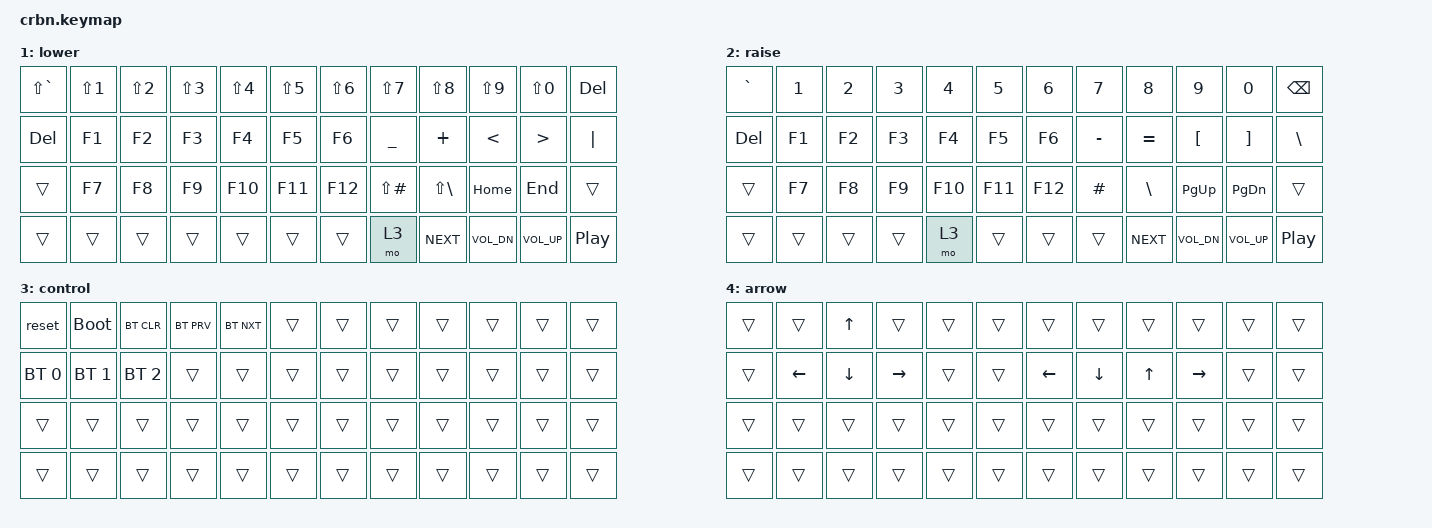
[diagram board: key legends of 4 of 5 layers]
/*
 * Copyright (c) 2020 The ZMK Contributors
 *
 * SPDX-License-Identifier: MIT
 */

#include <behaviors.dtsi>
#include <dt-bindings/zmk/keys.h>
#include <dt-bindings/zmk/bt.h>


        /*           36 Keys
        ╭──────────────╮       ╭──────────────╮
        │ 0  1  2  3  4│       │ 7  8  9 10 11│
        │12 13 14 15 16│       │19 20 21 22 23│
        │24 25 26 27 28│───────│31 32 33 34 35│
        │36    38 39 40│ 41 42 │43 44 45    47│
        ╰──────────────╯───────╰──────────────╯   */

/ {
	keymap {
		compatible = "zmk,keymap";

		default_layer {
			// -----------------------------------------------------------------------------------------
			// |   Q   |  W   |  E   |  R   |  T   |      |       |   Y   |  U   |  I   |   O   |   P   |
			// |   A   |  S   |  D   |  F   |  G   |      |       |   H   |  J   |  K   |   L   |   ;   |
			// |   Z   |  X   |  C   |  V   |  B   |              |   N   |  M   |  ,   |   .   |   /   |
			// |       | LCTL | LALT | LGUI | LOWR |     SPACE    |  RAIS | LARW | DARW | UARW  |  RARW |
			bindings = <
				&kp Q &kp W &kp E &kp R &kp T &trans              &trans &kp Y &kp U &kp I     &kp O   &kp P
				&kp A &kp S &kp D &kp F &kp G &trans              &trans &kp H &kp J &kp K     &kp L   &kp SEMI
				&kp Z &kp X &kp C &kp V &kp B &trans              &trans &kp N &kp M &kp COMMA &kp DOT &kp FSLH 
				&trans &trans &kp LALT &kp LGUI &lt 1 &trans      &trans &lt 2 &kp LCTRL &trans  &trans
			>;

			sensor-bindings = <&inc_dec_kp PG_UP PG_DN>;
		};

		lower {
			bindings = <
			&kp LS(GRAVE) &kp LS(N1) &kp LS(N2) &kp LS(N3) &kp LS(N4) &kp LS(N5) &kp LS(N6) &kp LS(N7) &kp LS(N8) &kp LS(N9) &kp LS(N0) &kp DEL
			&kp DEL &kp F1 &kp F2 &kp F3 &kp F4 &kp F5 &kp F6 &kp UNDER &kp PLUS &kp LT &kp GT &kp PIPE
			&trans &kp F7 &kp F8 &kp F9 &kp F10 &kp F11 &kp F12 &kp LS(HASH) &kp LS(BSLH) &kp HOME &kp END &trans
			&trans &trans &trans &trans &trans &trans &trans &mo 3 &kp C_NEXT &kp C_VOL_DN &kp C_VOL_UP &kp C_PP
			>;

			sensor-bindings = <&inc_dec_kp C_VOL_UP C_VOL_DN>;
		};

		raise {
			bindings = <
				&kp GRAVE &kp N1 &kp N2 &kp N3 &kp N4 &kp N5 &kp N6 &kp N7 &kp N8 &kp N9 &kp N0 &kp BSPC
				&kp DEL &kp F1 &kp F2 &kp F3 &kp F4 &kp F5 &kp F6 &kp MINUS &kp EQUAL &kp LBKT &kp RBKT &kp BSLH
				&trans &kp F7 &kp F8 &kp F9 &kp F10 &kp F11 &kp F12 &kp HASH &kp BSLH &kp PG_UP &kp PG_DN &trans
				&trans &trans &trans &trans &mo 3 &trans &trans &trans &kp C_NEXT &kp C_VOL_DN &kp C_VOL_UP &kp C_PP
			>;

			sensor-bindings = <&inc_dec_kp PG_UP PG_DN>;
		};

		control {
			bindings = <
				&reset &bootloader &bt BT_CLR &bt BT_PRV &bt BT_NXT &trans &trans &trans &trans &trans &trans &trans
				&bt BT_SEL 0 &bt BT_SEL 1 &bt BT_SEL 2 &trans &trans &trans &trans &trans &trans &trans &trans &trans
				&trans &trans &trans &trans &trans &trans &trans &trans &trans &trans &trans &trans
				&trans &trans &trans &trans &trans &trans &trans &trans &trans &trans &trans &trans
			>;
		};

		arrow {
		bindings = <
			&trans &trans   &kp UP       &trans &trans &trans &trans &trans &trans &trans &trans &trans
			&trans &kp LEFT &kp DOWN &kp RIGHT  &trans &trans &kp LEFT &kp DOWN &kp UP &kp RIGHT &trans &trans
			&trans &trans   &trans       &trans &trans &trans &trans &trans &trans &trans &trans &trans
			&trans &trans   &trans       &trans &trans &trans &trans &trans &trans &trans &trans &trans
			>;
		};
	};
};
